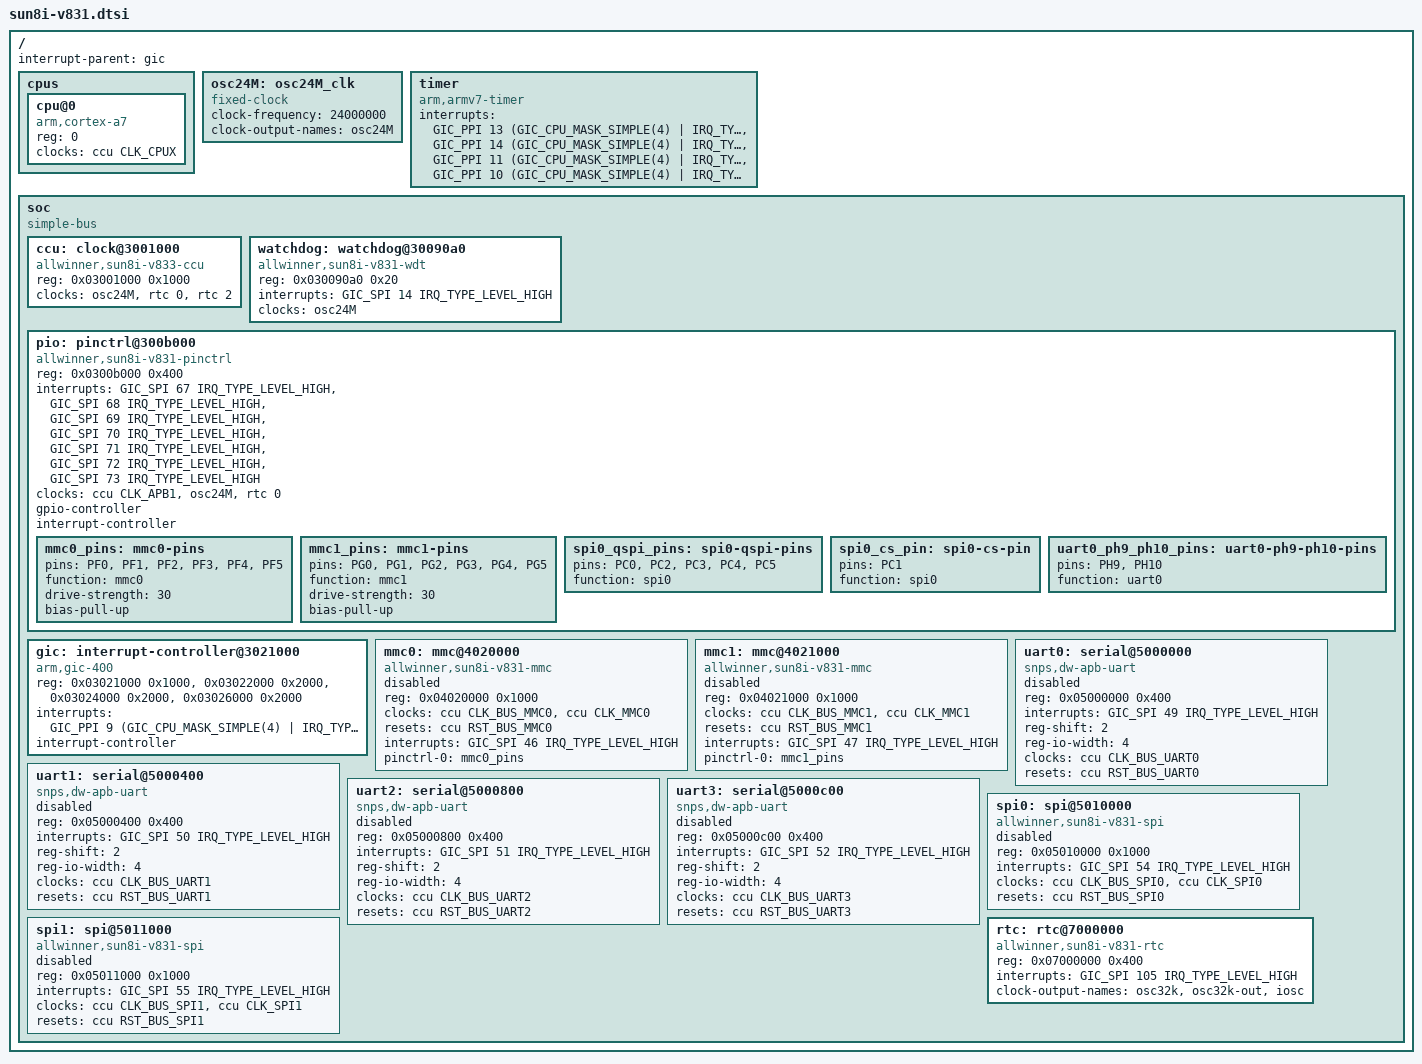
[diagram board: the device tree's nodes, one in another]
// SPDX-License-Identifier: (GPL-2.0+ OR MIT)
/*
 * Copyright (C) 2020 Icenowy Zheng <icenowy@aosc.io>
 */

#include <dt-bindings/interrupt-controller/arm-gic.h>
#include <dt-bindings/clock/sun8i-v833-ccu.h>
#include <dt-bindings/reset/sun8i-v833-ccu.h>

/ {
	interrupt-parent = <&gic>;
	#address-cells = <1>;
	#size-cells = <1>;

	cpus {
		#address-cells = <1>;
		#size-cells = <0>;

		cpu@0 {
			compatible = "arm,cortex-a7";
			device_type = "cpu";
			reg = <0>;
			clocks = <&ccu CLK_CPUX>;
		};
	};

	osc24M: osc24M_clk {
		#clock-cells = <0>;
		compatible = "fixed-clock";
		clock-frequency = <24000000>;
		clock-output-names = "osc24M";
	};

	timer {
		compatible = "arm,armv7-timer";
		interrupts = <GIC_PPI 13
			(GIC_CPU_MASK_SIMPLE(4) | IRQ_TYPE_LEVEL_HIGH)>,
			     <GIC_PPI 14
			(GIC_CPU_MASK_SIMPLE(4) | IRQ_TYPE_LEVEL_HIGH)>,
			     <GIC_PPI 11
			(GIC_CPU_MASK_SIMPLE(4) | IRQ_TYPE_LEVEL_HIGH)>,
			     <GIC_PPI 10
			(GIC_CPU_MASK_SIMPLE(4) | IRQ_TYPE_LEVEL_HIGH)>;
	};

	soc {
		compatible = "simple-bus";
		#address-cells = <1>;
		#size-cells = <1>;
		ranges;

		ccu: clock@3001000 {
			compatible = "allwinner,sun8i-v833-ccu";
			reg = <0x03001000 0x1000>;
			clocks = <&osc24M>, <&rtc 0>, <&rtc 2>;
			clock-names = "hosc", "losc", "iosc";
			#clock-cells = <1>;
			#reset-cells = <1>;
		};

		watchdog: watchdog@30090a0 {
			compatible = "allwinner,sun8i-v831-wdt",
				     "allwinner,sun6i-a31-wdt";
			reg = <0x030090a0 0x20>;
			interrupts = <GIC_SPI 14 IRQ_TYPE_LEVEL_HIGH>;
			clocks = <&osc24M>;
		};

		pio: pinctrl@300b000 {
			compatible = "allwinner,sun8i-v831-pinctrl";
			reg = <0x0300b000 0x400>;
			interrupts = <GIC_SPI 67 IRQ_TYPE_LEVEL_HIGH>,
				     <GIC_SPI 68 IRQ_TYPE_LEVEL_HIGH>,
				     <GIC_SPI 69 IRQ_TYPE_LEVEL_HIGH>,
				     <GIC_SPI 70 IRQ_TYPE_LEVEL_HIGH>,
				     <GIC_SPI 71 IRQ_TYPE_LEVEL_HIGH>,
				     <GIC_SPI 72 IRQ_TYPE_LEVEL_HIGH>,
				     <GIC_SPI 73 IRQ_TYPE_LEVEL_HIGH>;
			clocks = <&ccu CLK_APB1>, <&osc24M>, <&rtc 0>;
			clock-names = "apb", "hosc", "losc";
			gpio-controller;
			#gpio-cells = <3>;
			interrupt-controller;
			#interrupt-cells = <3>;

			mmc0_pins: mmc0-pins {
				pins = "PF0", "PF1", "PF2", "PF3",
				       "PF4", "PF5";
				function = "mmc0";
				drive-strength = <30>;
				bias-pull-up;
			};

			/omit-if-no-ref/
			mmc1_pins: mmc1-pins {
				pins = "PG0", "PG1", "PG2", "PG3",
				       "PG4", "PG5";
				function = "mmc1";
				drive-strength = <30>;
				bias-pull-up;
			};

			/omit-if-no-ref/
			spi0_qspi_pins: spi0-qspi-pins {
				pins = "PC0", "PC2", "PC3", "PC4", "PC5";
				function = "spi0";
			};

			/omit-if-no-ref/
			spi0_cs_pin: spi0-cs-pin {
				pins = "PC1";
				function = "spi0";
			};

			uart0_ph9_ph10_pins: uart0-ph9-ph10-pins {
				pins = "PH9", "PH10";
				function = "uart0";
			};
		};

		gic: interrupt-controller@3021000 {
			compatible = "arm,gic-400";
			reg = <0x03021000 0x1000>,
			      <0x03022000 0x2000>,
			      <0x03024000 0x2000>,
			      <0x03026000 0x2000>;
			interrupts = <GIC_PPI 9 (GIC_CPU_MASK_SIMPLE(4) | IRQ_TYPE_LEVEL_HIGH)>;
			interrupt-controller;
			#interrupt-cells = <3>;
		};

		mmc0: mmc@4020000 {
			compatible = "allwinner,sun8i-v831-mmc",
				     "allwinner,sun50i-a64-mmc";
			reg = <0x04020000 0x1000>;
			clocks = <&ccu CLK_BUS_MMC0>, <&ccu CLK_MMC0>;
			clock-names = "ahb", "mmc";
			resets = <&ccu RST_BUS_MMC0>;
			reset-names = "ahb";
			interrupts = <GIC_SPI 46 IRQ_TYPE_LEVEL_HIGH>;
			pinctrl-names = "default";
			pinctrl-0 = <&mmc0_pins>;
			status = "disabled";
			#address-cells = <1>;
			#size-cells = <0>;
		};

		mmc1: mmc@4021000 {
			compatible = "allwinner,sun8i-v831-mmc",
				     "allwinner,sun50i-a64-mmc";
			reg = <0x04021000 0x1000>;
			clocks = <&ccu CLK_BUS_MMC1>, <&ccu CLK_MMC1>;
			clock-names = "ahb", "mmc";
			resets = <&ccu RST_BUS_MMC1>;
			reset-names = "ahb";
			interrupts = <GIC_SPI 47 IRQ_TYPE_LEVEL_HIGH>;
			pinctrl-names = "default";
			pinctrl-0 = <&mmc1_pins>;
			status = "disabled";
			#address-cells = <1>;
			#size-cells = <0>;
		};

		uart0: serial@5000000 {
			compatible = "snps,dw-apb-uart";
			reg = <0x05000000 0x400>;
			interrupts = <GIC_SPI 49 IRQ_TYPE_LEVEL_HIGH>;
			reg-shift = <2>;
			reg-io-width = <4>;
			clocks = <&ccu CLK_BUS_UART0>;
			resets = <&ccu RST_BUS_UART0>;
			status = "disabled";
		};

		uart1: serial@5000400 {
			compatible = "snps,dw-apb-uart";
			reg = <0x05000400 0x400>;
			interrupts = <GIC_SPI 50 IRQ_TYPE_LEVEL_HIGH>;
			reg-shift = <2>;
			reg-io-width = <4>;
			clocks = <&ccu CLK_BUS_UART1>;
			resets = <&ccu RST_BUS_UART1>;
			status = "disabled";
		};

		uart2: serial@5000800 {
			compatible = "snps,dw-apb-uart";
			reg = <0x05000800 0x400>;
			interrupts = <GIC_SPI 51 IRQ_TYPE_LEVEL_HIGH>;
			reg-shift = <2>;
			reg-io-width = <4>;
			clocks = <&ccu CLK_BUS_UART2>;
			resets = <&ccu RST_BUS_UART2>;
			status = "disabled";
		};

		uart3: serial@5000c00 {
			compatible = "snps,dw-apb-uart";
			reg = <0x05000c00 0x400>;
			interrupts = <GIC_SPI 52 IRQ_TYPE_LEVEL_HIGH>;
			reg-shift = <2>;
			reg-io-width = <4>;
			clocks = <&ccu CLK_BUS_UART3>;
			resets = <&ccu RST_BUS_UART3>;
			status = "disabled";
		};

		spi0: spi@5010000 {
			compatible = "allwinner,sun8i-v831-spi",
				     "allwinner,sun50i-h6-spi",
				     "allwinner,sun8i-h3-spi";
			reg = <0x05010000 0x1000>;
			interrupts = <GIC_SPI 54 IRQ_TYPE_LEVEL_HIGH>;
			clocks = <&ccu CLK_BUS_SPI0>, <&ccu CLK_SPI0>;
			clock-names = "ahb", "mod";
			resets = <&ccu RST_BUS_SPI0>;
			status = "disabled";
			#address-cells = <1>;
			#size-cells = <0>;
		};

		spi1: spi@5011000 {
			compatible = "allwinner,sun8i-v831-spi",
				     "allwinner,sun50i-h6-spi",
				     "allwinner,sun8i-h3-spi";
			reg = <0x05011000 0x1000>;
			interrupts = <GIC_SPI 55 IRQ_TYPE_LEVEL_HIGH>;
			clocks = <&ccu CLK_BUS_SPI1>, <&ccu CLK_SPI1>;
			clock-names = "ahb", "mod";
			resets = <&ccu RST_BUS_SPI1>;
			status = "disabled";
			#address-cells = <1>;
			#size-cells = <0>;
		};

		rtc: rtc@7000000 {
			compatible = "allwinner,sun8i-v831-rtc";
			reg = <0x07000000 0x400>;
			interrupts = <GIC_SPI 105 IRQ_TYPE_LEVEL_HIGH>;
			clock-output-names = "osc32k", "osc32k-out", "iosc";
			#clock-cells = <1>;
		};
	};
};
